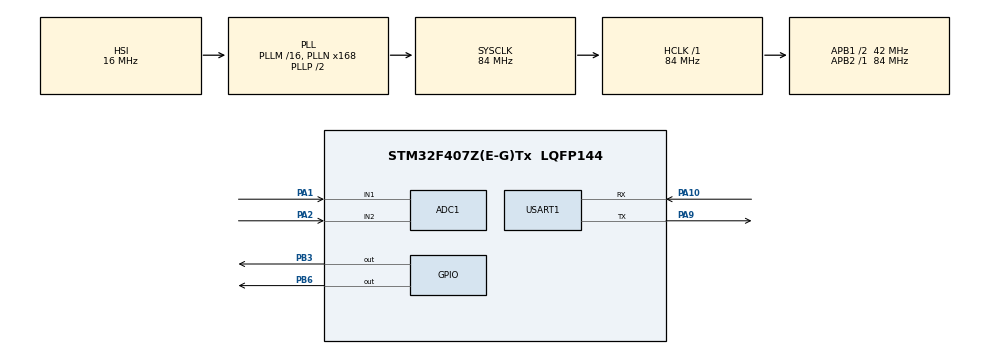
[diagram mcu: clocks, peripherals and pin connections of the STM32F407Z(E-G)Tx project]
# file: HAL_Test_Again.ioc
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ADC1.Channel-0\#ChannelRegularConversion=ADC_CHANNEL_1
ADC1.Channel-1\#ChannelRegularConversion=ADC_CHANNEL_2
ADC1.ContinuousConvMode=ENABLE
ADC1.NbrOfConversion=2
ADC1.NbrOfConversionFlag=1
ADC1.Rank-0\#ChannelRegularConversion=1
ADC1.Rank-1\#ChannelRegularConversion=2
ADC1.SamplingTime-0\#ChannelRegularConversion=ADC_SAMPLETIME_56CYCLES
ADC1.SamplingTime-1\#ChannelRegularConversion=ADC_SAMPLETIME_56CYCLES
ADC1.ScanConvMode=ENABLE
ADC1.master=1
Dma.ADC1.0.Direction=DMA_PERIPH_TO_MEMORY
Dma.ADC1.0.FIFOMode=DMA_FIFOMODE_DISABLE
Dma.ADC1.0.Instance=DMA2_Stream0
Dma.ADC1.0.MemDataAlignment=DMA_MDATAALIGN_HALFWORD
Dma.ADC1.0.MemInc=DMA_MINC_ENABLE
Dma.ADC1.0.Mode=DMA_CIRCULAR
Dma.ADC1.0.PeriphDataAlignment=DMA_PDATAALIGN_HALFWORD
Dma.ADC1.0.PeriphInc=DMA_PINC_DISABLE
Dma.ADC1.0.Priority=DMA_PRIORITY_LOW
Dma.Request0=ADC1
Dma.Request1=USART1_TX
Dma.USART1_TX.1.Direction=DMA_MEMORY_TO_PERIPH
Dma.USART1_TX.1.FIFOMode=DMA_FIFOMODE_DISABLE
Dma.USART1_TX.1.Instance=DMA2_Stream7
Dma.USART1_TX.1.MemDataAlignment=DMA_MDATAALIGN_BYTE
Dma.USART1_TX.1.MemInc=DMA_MINC_ENABLE
Dma.USART1_TX.1.Mode=DMA_NORMAL
Dma.USART1_TX.1.PeriphDataAlignment=DMA_PDATAALIGN_BYTE
Dma.USART1_TX.1.PeriphInc=DMA_PINC_DISABLE
Dma.USART1_TX.1.Priority=DMA_PRIORITY_MEDIUM
Mcu.Family=STM32F4
Mcu.Name=STM32F407Z(E-G)Tx
Mcu.Package=LQFP144
NVIC.DMA2_Stream0_IRQn=true\:0\:0\:false\:false\:true\:false\:true\:true
NVIC.DMA2_Stream7_IRQn=true\:0\:0\:false\:false\:true\:false\:true\:true
NVIC.PriorityGroup=NVIC_PRIORITYGROUP_4
NVIC.TIM1_UP_TIM10_IRQn=true\:2\:0\:true\:false\:true\:true\:true\:true
NVIC.USART1_IRQn=true\:1\:0\:true\:false\:true\:true\:true\:true
PA1.Signal=ADCx_IN1
PA10.Mode=Asynchronous
PA10.Signal=USART1_RX
PA13.Mode=Serial_Wire
PA13.Signal=SYS_JTMS-SWDIO
PA14.Mode=Serial_Wire
PA14.Signal=SYS_JTCK-SWCLK
PA2.Signal=ADCx_IN2
PA9.Mode=Asynchronous
PA9.Signal=USART1_TX
PB3.GPIO_ModeDefaultOutputPP=GPIO_MODE_OUTPUT_OD
PB3.GPIO_PuPd=GPIO_PULLUP
PB3.GPIO_Speed=GPIO_SPEED_FREQ_HIGH
PB3.PinState=GPIO_PIN_SET
PB3.Signal=GPIO_Output
PB6.GPIO_ModeDefaultOutputPP=GPIO_MODE_OUTPUT_OD
PB6.GPIO_PuPd=GPIO_PULLUP
PB6.GPIO_Speed=GPIO_SPEED_FREQ_HIGH
PB6.PinState=GPIO_PIN_SET
PB6.Signal=GPIO_Output
PH0-OSC_IN.Mode=HSE-External-Clock-Source
PH0-OSC_IN.Signal=RCC_OSC_IN
PH1-OSC_OUT.Mode=HSE-External-Clock-Source
PH1-OSC_OUT.Signal=RCC_OSC_OUT
ProjectManager.HeapSize=0x200
ProjectManager.StackSize=0x400
ProjectManager.TargetToolchain=MDK-ARM V5.32
RCC.48MHZClocksFreq_Value=42000000
RCC.AHBFreq_Value=84000000
RCC.APB1CLKDivider=RCC_HCLK_DIV2
RCC.APB1Freq_Value=42000000
RCC.APB1TimFreq_Value=84000000
RCC.APB2Freq_Value=84000000
RCC.APB2TimFreq_Value=84000000
RCC.CortexFreq_Value=84000000
RCC.HCLKFreq_Value=84000000
RCC.HSE_VALUE=16000000
RCC.HSI_VALUE=16000000
RCC.LSE_VALUE=32768
RCC.PLLN=168
RCC.SYSCLKFreq_VALUE=84000000
RCC.SYSCLKSource=RCC_SYSCLKSOURCE_PLLCLK
RCC.VCOOutputFreq_Value=168000000
SH.ADCx_IN1.0=ADC1_IN1,IN1
SH.ADCx_IN2.0=ADC1_IN2,IN2
TIM1.AutoReloadPreload=TIM_AUTORELOAD_PRELOAD_ENABLE
TIM1.Period=999
TIM1.Prescaler=83
TIM1.RepetitionCounter=9
USART1.VirtualMode=VM_ASYNC
VP_TIM1_VS_ClockSourceINT.Mode=Internal
board=custom

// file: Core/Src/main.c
/* USER CODE BEGIN Header */
/**
  ******************************************************************************
  * @file           : main.c
  * @brief          : Main program body
  ******************************************************************************
  * @attention
  *
  * Copyright (c) 2025 STMicroelectronics.
  * All rights reserved.
  *
  * This software is licensed under terms that can be found in the LICENSE file
  * in the root directory of this software component.
  * If no LICENSE file comes with this software, it is provided AS-IS.
  *
  ******************************************************************************
  */
/* USER CODE END Header */
#include "main.h"
#include "adc.h"
#include "dma.h"
#include "tim.h"
#include "usart.h"
#include "gpio.h"

/* USER CODE BEGIN Includes */
#include "stdio.h"
#include <string.h>
#include "bsp_adc_dma.h"
#include "bsp_tim.h"
#include "bsp_soft_i2c.h"
#include "bsp_ir_red_cal2.h"
#include "bsp_usart_dma.h"
/* USER CODE END Includes */

/* USER CODE BEGIN PV */
uint8_t fifo_buffer[6] = {0};
uint8_t reg_commands[8] = {0x04, 0x05, 0x06, 0x08, 0x0A, 0x0C, 0x0D, 0x09};
uint8_t commands[8] = {0x00, 0x00, 0x00, 0x00, 0x07, 0x18, 0x18, 0x03};

/* USER CODE END PV */

void SystemClock_Config(void);

int main(void)
{

  /* MCU Configuration--------------------------------------------------------*/

  /* Reset of all peripherals, Initializes the Flash interface and the Systick. */
  HAL_Init();

  /* Configure the system clock */
  SystemClock_Config();

  /* Initialize all configured peripherals */
  MX_GPIO_Init();
  MX_DMA_Init();
  MX_ADC1_Init();
  MX_TIM1_Init();
  MX_USART1_UART_Init();
  /* USER CODE BEGIN 2 */

	HR_Device_Init(0x57, reg_commands, commands, 8);

  BSP_TIM_Init(&htim1);
  BSP_TIM_Start_IT();

	memset(&smooth_buf, 0, sizeof(smooth_buf));
  /* USER CODE END 2 */

  /* Infinite loop */
  while (1)
  {

  }
}

void SystemClock_Config(void)
{
  RCC_OscInitTypeDef RCC_OscInitStruct = {0};
  RCC_ClkInitTypeDef RCC_ClkInitStruct = {0};

  /** Configure the main internal regulator output voltage
  */
  __HAL_RCC_PWR_CLK_ENABLE();
  __HAL_PWR_VOLTAGESCALING_CONFIG(PWR_REGULATOR_VOLTAGE_SCALE1);

  /** Initializes the RCC Oscillators according to the specified parameters
  * in the RCC_OscInitTypeDef structure.
  */
  RCC_OscInitStruct.OscillatorType = RCC_OSCILLATORTYPE_HSI;
  RCC_OscInitStruct.HSIState = RCC_HSI_ON;
  RCC_OscInitStruct.HSICalibrationValue = RCC_HSICALIBRATION_DEFAULT;
  RCC_OscInitStruct.PLL.PLLState = RCC_PLL_ON;
  RCC_OscInitStruct.PLL.PLLSource = RCC_PLLSOURCE_HSI;
  RCC_OscInitStruct.PLL.PLLM = 16;
  RCC_OscInitStruct.PLL.PLLN = 168;
  RCC_OscInitStruct.PLL.PLLP = RCC_PLLP_DIV2;
  RCC_OscInitStruct.PLL.PLLQ = 4;
  if (HAL_RCC_OscConfig(&RCC_OscInitStruct) != HAL_OK)
  {
    Error_Handler();
  }

  /** Initializes the CPU, AHB and APB buses clocks
  */
  RCC_ClkInitStruct.ClockType = RCC_CLOCKTYPE_HCLK|RCC_CLOCKTYPE_SYSCLK
                              |RCC_CLOCKTYPE_PCLK1|RCC_CLOCKTYPE_PCLK2;
  RCC_ClkInitStruct.SYSCLKSource = RCC_SYSCLKSOURCE_PLLCLK;
  RCC_ClkInitStruct.AHBCLKDivider = RCC_SYSCLK_DIV1;
  RCC_ClkInitStruct.APB1CLKDivider = RCC_HCLK_DIV2;
  RCC_ClkInitStruct.APB2CLKDivider = RCC_HCLK_DIV1;

  if (HAL_RCC_ClockConfig(&RCC_ClkInitStruct, FLASH_LATENCY_2) != HAL_OK)
  {
    Error_Handler();
  }
}

void Error_Handler(void)
{
  __disable_irq();
  while (1)
  {
  }
}
